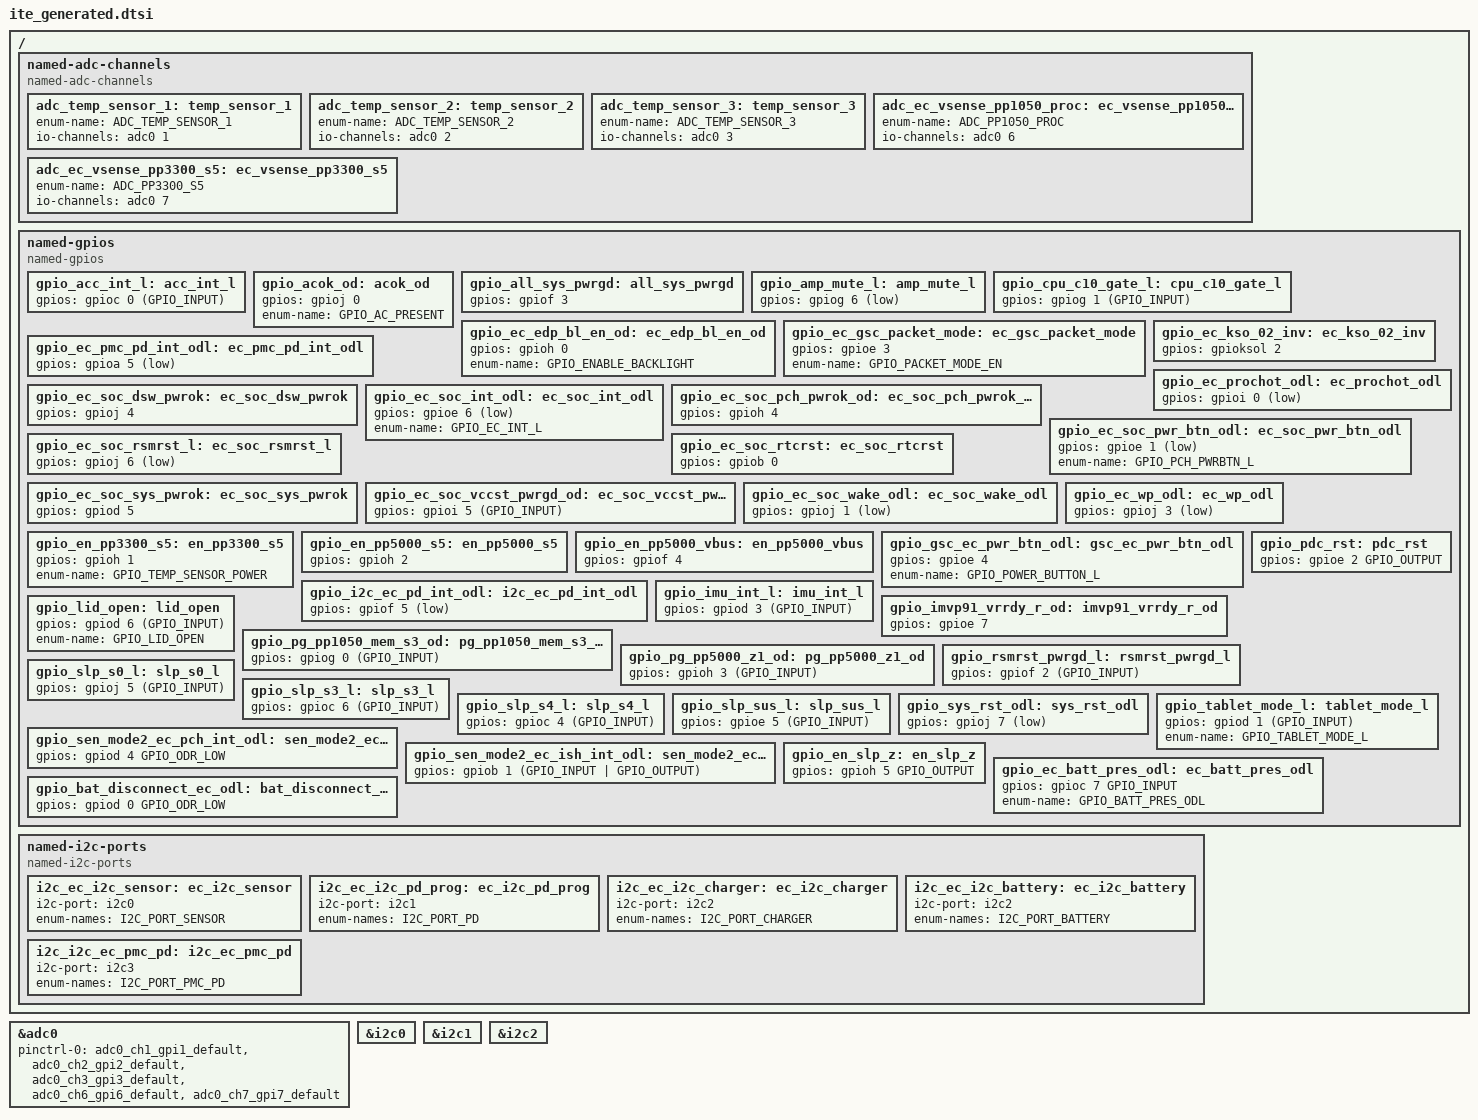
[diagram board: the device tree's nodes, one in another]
/* Copyright 2025 The ChromiumOS Authors
 * Use of this source code is governed by a BSD-style license that can be
 * found in the LICENSE file.
 *
 * This file is auto-generated - do not edit!
 */

/ {

	named-adc-channels {
		compatible = "named-adc-channels";

		adc_temp_sensor_1: temp_sensor_1 {
			enum-name = "ADC_TEMP_SENSOR_1";
			io-channels = <&adc0 1>;
		};
		adc_temp_sensor_2: temp_sensor_2 {
			enum-name = "ADC_TEMP_SENSOR_2";
			io-channels = <&adc0 2>;
		};
		adc_temp_sensor_3: temp_sensor_3 {
			enum-name = "ADC_TEMP_SENSOR_3";
			io-channels = <&adc0 3>;
		};
		adc_ec_vsense_pp1050_proc: ec_vsense_pp1050_proc {
			enum-name = "ADC_PP1050_PROC";
			io-channels = <&adc0 6>;
		};
		adc_ec_vsense_pp3300_s5: ec_vsense_pp3300_s5 {
			enum-name = "ADC_PP3300_S5";
			io-channels = <&adc0 7>;
		};
	};

	named-gpios {
		compatible = "named-gpios";

		gpio_acc_int_l: acc_int_l {
			gpios = <&gpioc 0 (GPIO_INPUT)>;
		};
		gpio_acok_od: acok_od {
			gpios = <&gpioj 0 (GPIO_OUTPUT | GPIO_ACTIVE_HIGH)>;
			enum-name = "GPIO_AC_PRESENT";
		};
		gpio_all_sys_pwrgd: all_sys_pwrgd {
			gpios = <&gpiof 3 (GPIO_OUTPUT | GPIO_ACTIVE_HIGH | GPIO_OUTPUT_INIT_LOW)>;
		};
		gpio_amp_mute_l: amp_mute_l {
			gpios = <&gpiog 6 (GPIO_OUTPUT | GPIO_ACTIVE_LOW | GPIO_OUTPUT_INIT_HIGH)>;
		};
		gpio_cpu_c10_gate_l: cpu_c10_gate_l {
			gpios = <&gpiog 1 (GPIO_INPUT)>;
		};
		gpio_ec_edp_bl_en_od: ec_edp_bl_en_od {
			gpios = <&gpioh 0 (GPIO_OUTPUT | GPIO_OPEN_DRAIN | GPIO_ACTIVE_HIGH | GPIO_OUTPUT_INIT_LOW)>;
			enum-name = "GPIO_ENABLE_BACKLIGHT";
		};
		gpio_ec_gsc_packet_mode: ec_gsc_packet_mode {
			gpios = <&gpioe 3 (GPIO_OUTPUT | GPIO_ACTIVE_HIGH | GPIO_OUTPUT_INIT_HIGH)>;
			enum-name = "GPIO_PACKET_MODE_EN";
		};
		gpio_ec_kso_02_inv: ec_kso_02_inv {
			gpios = <&gpioksol 2 (GPIO_OUTPUT | GPIO_ACTIVE_HIGH | GPIO_OUTPUT_INIT_HIGH)>;
		};
		gpio_ec_pmc_pd_int_odl: ec_pmc_pd_int_odl {
			gpios = <&gpioa 5 (GPIO_OUTPUT | GPIO_OPEN_DRAIN | GPIO_ACTIVE_LOW)>;
		};
		gpio_ec_prochot_odl: ec_prochot_odl {
			gpios = <&gpioi 0 (GPIO_OUTPUT | GPIO_OPEN_DRAIN | GPIO_ACTIVE_LOW | GPIO_OUTPUT_INIT_HIGH)>;
		};
		gpio_ec_soc_dsw_pwrok: ec_soc_dsw_pwrok {
			gpios = <&gpioj 4 (GPIO_OUTPUT | GPIO_ACTIVE_HIGH | GPIO_OUTPUT_INIT_LOW)>;
		};
		gpio_ec_soc_int_odl: ec_soc_int_odl {
			gpios = <&gpioe 6 (GPIO_OUTPUT | GPIO_OPEN_DRAIN | GPIO_ACTIVE_LOW | GPIO_OUTPUT_INIT_HIGH)>;
			enum-name = "GPIO_EC_INT_L";
		};
		gpio_ec_soc_pch_pwrok_od: ec_soc_pch_pwrok_od {
			gpios = <&gpioh 4 (GPIO_OUTPUT | GPIO_OPEN_DRAIN | GPIO_ACTIVE_HIGH | GPIO_OUTPUT_INIT_HIGH)>;
		};
		gpio_ec_soc_pwr_btn_odl: ec_soc_pwr_btn_odl {
			gpios = <&gpioe 1 (GPIO_OUTPUT | GPIO_OPEN_DRAIN | GPIO_ACTIVE_LOW | GPIO_OUTPUT_INIT_HIGH)>;
			enum-name = "GPIO_PCH_PWRBTN_L";
		};
		gpio_ec_soc_rsmrst_l: ec_soc_rsmrst_l {
			gpios = <&gpioj 6 (GPIO_OUTPUT | GPIO_ACTIVE_LOW | GPIO_OUTPUT_INIT_HIGH)>;
		};
		gpio_ec_soc_rtcrst: ec_soc_rtcrst {
			gpios = <&gpiob 0 (GPIO_OUTPUT | GPIO_ACTIVE_HIGH | GPIO_OUTPUT_INIT_LOW)>;
		};
		gpio_ec_soc_sys_pwrok: ec_soc_sys_pwrok {
			gpios = <&gpiod 5 (GPIO_OUTPUT | GPIO_ACTIVE_HIGH | GPIO_OUTPUT_INIT_LOW)>;
		};
		gpio_ec_soc_vccst_pwrgd_od: ec_soc_vccst_pwrgd_od {
			gpios = <&gpioi 5 (GPIO_INPUT)>;
		};
		gpio_ec_soc_wake_odl: ec_soc_wake_odl {
			gpios = <&gpioj 1 (GPIO_OUTPUT | GPIO_OPEN_DRAIN | GPIO_ACTIVE_LOW | GPIO_OUTPUT_INIT_HIGH)>;
		};
		gpio_ec_wp_odl: ec_wp_odl {
			gpios = <&gpioj 3 (GPIO_INPUT | GPIO_ACTIVE_LOW)>;
		};
		gpio_en_pp3300_s5: en_pp3300_s5 {
			gpios = <&gpioh 1 (GPIO_OUTPUT | GPIO_ACTIVE_HIGH | GPIO_OUTPUT_INIT_LOW)>;
			enum-name = "GPIO_TEMP_SENSOR_POWER";
		};
		gpio_en_pp5000_s5: en_pp5000_s5 {
			gpios = <&gpioh 2 (GPIO_OUTPUT | GPIO_ACTIVE_HIGH | GPIO_OUTPUT_INIT_LOW)>;
		};
		gpio_en_pp5000_vbus: en_pp5000_vbus {
			gpios = <&gpiof 4 (GPIO_OUTPUT | GPIO_ACTIVE_HIGH | GPIO_OUTPUT_INIT_LOW)>;
		};
		gpio_gsc_ec_pwr_btn_odl: gsc_ec_pwr_btn_odl {
			gpios = <&gpioe 4 (GPIO_INPUT | GPIO_PULL_UP)>;
			enum-name = "GPIO_POWER_BUTTON_L";
		};
		gpio_i2c_ec_pd_int_odl: i2c_ec_pd_int_odl {
			gpios = <&gpiof 5 (GPIO_INPUT | GPIO_ACTIVE_LOW)>;
		};
		gpio_imu_int_l: imu_int_l {
			gpios = <&gpiod 3 (GPIO_INPUT)>;
		};
		gpio_imvp91_vrrdy_r_od: imvp91_vrrdy_r_od {
			gpios = <&gpioe 7 (GPIO_OUTPUT | GPIO_OPEN_DRAIN | GPIO_ACTIVE_HIGH | GPIO_OUTPUT_INIT_LOW)>;
		};
		gpio_lid_open: lid_open {
			gpios = <&gpiod 6 (GPIO_INPUT)>;
			enum-name = "GPIO_LID_OPEN";
		};
		gpio_pdc_rst: pdc_rst {
			gpios = <&gpioe 2 GPIO_OUTPUT>;
		};
		gpio_pg_pp1050_mem_s3_od: pg_pp1050_mem_s3_od {
			gpios = <&gpiog 0 (GPIO_INPUT)>;
		};
		gpio_pg_pp5000_z1_od: pg_pp5000_z1_od {
			gpios = <&gpioh 3 (GPIO_INPUT)>;
		};
		gpio_rsmrst_pwrgd_l: rsmrst_pwrgd_l {
			gpios = <&gpiof 2 (GPIO_INPUT)>;
		};
		gpio_slp_s0_l: slp_s0_l {
			gpios = <&gpioj 5 (GPIO_INPUT)>;
		};
		gpio_slp_s3_l: slp_s3_l {
			gpios = <&gpioc 6 (GPIO_INPUT)>;
		};
		gpio_slp_s4_l: slp_s4_l {
			gpios = <&gpioc 4 (GPIO_INPUT)>;
		};
		gpio_slp_sus_l: slp_sus_l {
			gpios = <&gpioe 5 (GPIO_INPUT)>;
		};
		gpio_sys_rst_odl: sys_rst_odl {
			gpios = <&gpioj 7 (GPIO_OUTPUT | GPIO_OPEN_DRAIN | GPIO_ACTIVE_LOW)>;
		};
		gpio_tablet_mode_l: tablet_mode_l {
			gpios = <&gpiod 1 (GPIO_INPUT)>;
			enum-name = "GPIO_TABLET_MODE_L";
		};
		gpio_sen_mode2_ec_pch_int_odl: sen_mode2_ec_pch_int_odl {
			gpios = <&gpiod 4 GPIO_ODR_LOW>;
		};
		gpio_sen_mode2_ec_ish_int_odl: sen_mode2_ec_ish_int_odl {
			gpios = <&gpiob 1 (GPIO_INPUT | GPIO_OUTPUT)>;
		};
		gpio_en_slp_z: en_slp_z {
			gpios = <&gpioh 5 GPIO_OUTPUT>;
		};
		gpio_ec_batt_pres_odl: ec_batt_pres_odl {
			gpios = <&gpioc 7 GPIO_INPUT>;
			enum-name = "GPIO_BATT_PRES_ODL";
		};
		gpio_bat_disconnect_ec_odl: bat_disconnect_ec_odl {
			gpios = <&gpiod 0 GPIO_ODR_LOW>;
		};
	};

	named-i2c-ports {
		compatible = "named-i2c-ports";

		i2c_ec_i2c_sensor: ec_i2c_sensor {
			i2c-port = <&i2c0>;
			enum-names = "I2C_PORT_SENSOR";
		};
		i2c_ec_i2c_pd_prog: ec_i2c_pd_prog {
			i2c-port = <&i2c1>;
			enum-names = "I2C_PORT_PD";
		};
		i2c_ec_i2c_charger: ec_i2c_charger {
			i2c-port = <&i2c2>;
			enum-names = "I2C_PORT_CHARGER";
		};
		i2c_ec_i2c_battery: ec_i2c_battery {
			i2c-port = <&i2c2>;
			enum-names = "I2C_PORT_BATTERY";
		};
		i2c_i2c_ec_pmc_pd: i2c_ec_pmc_pd {
			i2c-port = <&i2c3>;
			enum-names = "I2C_PORT_PMC_PD";
		};
	};
};

&adc0 {
	pinctrl-0 = <&adc0_ch1_gpi1_default
		     &adc0_ch2_gpi2_default
		     &adc0_ch3_gpi3_default
		     &adc0_ch6_gpi6_default
		     &adc0_ch7_gpi7_default>;
	pinctrl-names = "default";
	status = "okay";
};

&i2c0 {
	status = "okay";
};

&i2c1 {
	status = "okay";
};

&i2c2 {
	status = "okay";
};
